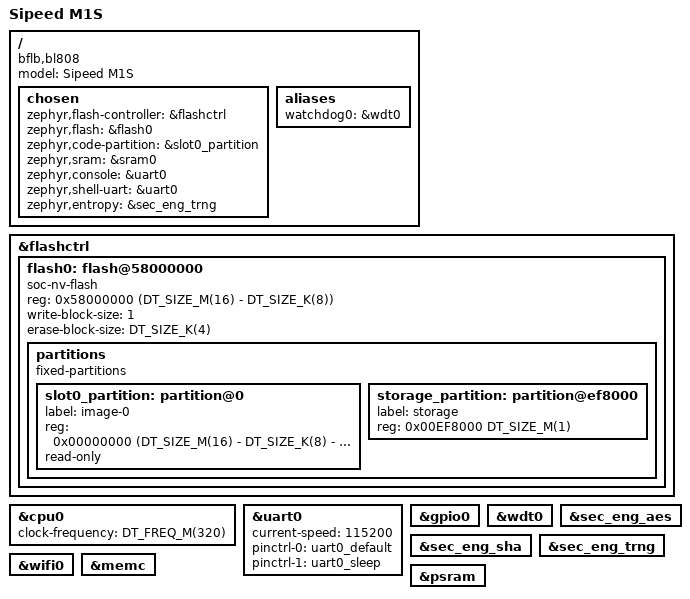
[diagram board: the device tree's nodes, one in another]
/*
 * Copyright The Zephyr Project Contributors
 *
 * SPDX-License-Identifier: Apache-2.0
 */

/dts-v1/;

#include <bflb/bl808x.dtsi>
#include "m1s-pinctrl.dtsi"

/ {
	model = "Sipeed M1S";
	compatible = "bflb,bl808";

	chosen {
		zephyr,flash-controller = &flashctrl;
		zephyr,flash = &flash0;
		zephyr,code-partition = &slot0_partition;
		zephyr,sram = &sram0;
		zephyr,console = &uart0;
		zephyr,shell-uart = &uart0;
		zephyr,entropy = &sec_eng_trng;
	};

	aliases {
		watchdog0 = &wdt0;
	};
};

&flashctrl {
	flash0: flash@58000000 {
		compatible = "soc-nv-flash", "winbond,w25q128jv";
		reg = <0x58000000 (DT_SIZE_M(16) - DT_SIZE_K(8))>;
		write-block-size = <1>;
		erase-block-size = <DT_SIZE_K(4)>;

		partitions {
			compatible = "fixed-partitions";
			#address-cells = <1>;
			#size-cells = <1>;

			slot0_partition: partition@0 {
				label = "image-0";
				reg = <0x00000000 (DT_SIZE_M(16) - DT_SIZE_K(8) - DT_SIZE_M(1))>;
				read-only;
			};

			storage_partition: partition@ef8000 {
				label = "storage";
				reg = <0x00EF8000 DT_SIZE_M(1)>;
			};
		};
	};
};

&cpu0 {
	clock-frequency = <DT_FREQ_M(320)>;
};

&uart0 {
	status = "okay";
	current-speed = <115200>;

	pinctrl-0 = <&uart0_default>;
	pinctrl-1 = <&uart0_sleep>;
	pinctrl-names = "default", "sleep";
};

&gpio0 {
	status = "okay";
};

&wdt0 {
	status = "okay";
};

&sec_eng_aes {
	status = "okay";
};

&sec_eng_sha {
	status = "okay";
};

&sec_eng_trng {
	status = "okay";
};

&wifi0 {
	status = "okay";
};

&memc {
	status = "okay";
};

&psram {
	status = "okay";
};
